# STM32H562 register map
File version: 0.1
CPU: CM33 r0p0, little endian, MPU, FPU, 4 interrupt priority bits
Registers are 32-bit, read-write, reset 0x0 unless marked. A register's access mark holds for its fields unless they carry their own. Offsets are from the block's base; [hi:lo] are bit positions; lines under a group give offsets from that group; {n}, {i} and the like mark numbered series.

## ADC1 — Analog to digital converter
Base 0x42028000
Same registers: ADC2 0x42028100, SEC_ADC1 0x52028000, SEC_ADC2 0x52028100
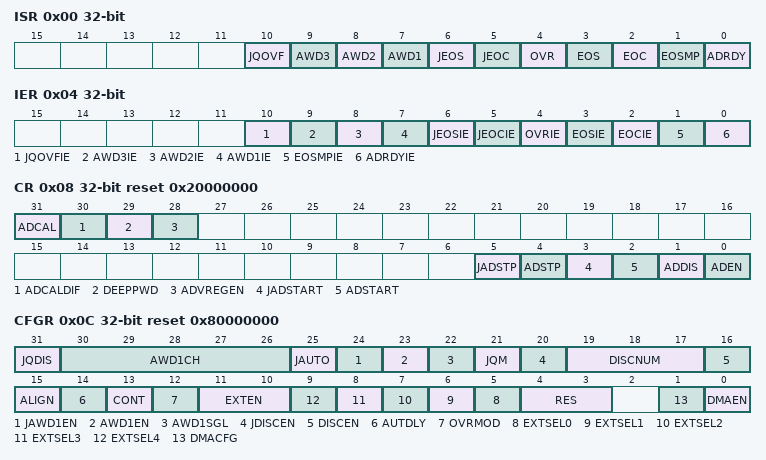
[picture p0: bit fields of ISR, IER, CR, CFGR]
0x00 ISR — ADC interrupt and status register
  [10] JQOVF — Injected context queue overflow This bit is set by hardware when an Overflow of the Injected Queue of Context occurs. It is cleared by software writing 1 to it. Refer to for more information.
  [9] AWD3 — Analog watchdog 3 flag This bit is set by hardware when the converted voltage crosses the values programmed in the fields LT3[7:0] and HT3[7:0] of ADC_TR3 register. It is cleared by software writing 1 to it.
  [8] AWD2 — Analog watchdog 2 flag This bit is set by hardware when the converted voltage crosses the values programmed in the fields LT2[7:0] and HT2[7:0] of ADC_TR2 register. It is cleared by software writing 1 to it.
  [7] AWD1 — Analog watchdog 1 flag This bit is set by hardware when the converted voltage crosses the values programmed in the fields LT1[11:0] and HT1[11:0] of ADC_TR1 register. It is cleared by software. writing 1 to it.
  [6] JEOS — Injected channel end of sequence flag This bit is set by hardware at the end of the conversions of all injected channels in the group. It is cleared by software writing 1 to it.
  [5] JEOC — Injected channel end of conversion flag This bit is set by hardware at the end of each injected conversion of a channel when a new data is available in the corresponding ADC_JDRy register. It is cleared by software writing 1 to it or by reading the corresponding ADC_JDRy register
  [4] OVR — ADC overrun This bit is set by hardware when an overrun occurs on a regular channel, meaning that a new conversion has completed while the EOC flag was already set. It is cleared by software writing 1 to it.
  [3] EOS — End of regular sequence flag This bit is set by hardware at the end of the conversions of a regular sequence of channels. It is cleared by software writing 1 to it.
  [2] EOC — End of conversion flag This bit is set by hardware at the end of each regular conversion of a channel when a new data is available in the ADC_DR register. It is cleared by software writing 1 to it or by reading the ADC_DR register
  [1] EOSMP — End of sampling flag This bit is set by hardware during the conversion of any channel (only for regular channels), at the end of the sampling phase.
  [0] ADRDY — ADC ready This bit is set by hardware after the ADC has been enabled (ADEN = 1) and when the ADC reaches a state where it is ready to accept conversion requests. It is cleared by software writing 1 to it.
0x04 IER — ADC interrupt enable register
  [10] JQOVFIE — Injected context queue overflow interrupt enable This bit is set and cleared by software to enable/disable the Injected Context Queue Overflow interrupt. Note: The software is allowed to write this bit only when JADSTART = 0 (which ensures that no injected conversion is ongoing).
  [9] AWD3IE — Analog watchdog 3 interrupt enable This bit is set and cleared by software to enable/disable the analog watchdog 2 interrupt. Note: The software is allowed to write this bit only when ADSTART = 0 and JADSTART = 0 (which ensures that no conversion is ongoing).
  [8] AWD2IE — Analog watchdog 2 interrupt enable This bit is set and cleared by software to enable/disable the analog watchdog 2 interrupt. Note: The software is allowed to write this bit only when ADSTART = 0 and JADSTART = 0 (which ensures that no conversion is ongoing).
  [7] AWD1IE — Analog watchdog 1 interrupt enable This bit is set and cleared by software to enable/disable the analog watchdog 1 interrupt. Note: The software is allowed to write this bit only when ADSTART = 0 and JADSTART = 0 (which ensures that no conversion is ongoing).
  [6] JEOSIE — End of injected sequence of conversions interrupt enable This bit is set and cleared by software to enable/disable the end of injected sequence of conversions interrupt. Note: The software is allowed to write this bit only when JADSTART = 0 (which ensures that no injected conversion is ongoing).
  [5] JEOCIE — End of injected conversion interrupt enable This bit is set and cleared by software to enable/disable the end of an injected conversion interrupt. Note: The software is allowed to write this bit only when JADSTART = 0 (which ensures that no injected conversion is ongoing).
  [4] OVRIE — Overrun interrupt enable This bit is set and cleared by software to enable/disable the Overrun interrupt of a regular conversion. Note: The software is allowed to write this bit only when ADSTART = 0 (which ensures that no regular conversion is ongoing).
  [3] EOSIE — End of regular sequence of conversions interrupt enable This bit is set and cleared by software to enable/disable the end of regular sequence of conversions interrupt. Note: The software is allowed to write this bit only when ADSTART = 0 (which ensures that no regular conversion is ongoing).
  [2] EOCIE — End of regular conversion interrupt enable This bit is set and cleared by software to enable/disable the end of a regular conversion interrupt. Note: The software is allowed to write this bit only when ADSTART = 0 (which ensures that no regular conversion is ongoing).
  [1] EOSMPIE — End of sampling flag interrupt enable for regular conversions This bit is set and cleared by software to enable/disable the end of the sampling phase interrupt for regular conversions. Note: The software is allowed to write this bit only when ADSTART = 0 (which ensures that no regular conversion is ongoing).
  [0] ADRDYIE — ADC ready interrupt enable This bit is set and cleared by software to enable/disable the ADC Ready interrupt. Note: The software is allowed to write this bit only when ADSTART = 0 and JADSTART = 0 (which ensures that no conversion is ongoing).
0x08 CR reset 0x20000000 — ADC control register
  [31] ADCAL — ADC calibration This bit is set by software to start the calibration of the ADC. Program first the bit ADCALDIF to determine if this calibration applies for Single-ended or Differential inputs mode. It is cleared by hardware after calibration is complete. Note: The software is allowed to launch a calibration by setting ADCAL only when ADEN = 0. The software is allowed to update the calibration factor by writing ADC_CALFACT only when ADEN = 1 and ADSTART = 0 and JADSTART = 0 (ADC enabled and no conversion is ongoing)
  [30] ADCALDIF — Differential mode for calibration This bit is set and cleared by software to configure the Single-ended or Differential inputs mode for the calibration. Note: The software is allowed to write this bit only when the ADC is disabled and is not calibrating (ADCAL = 0, JADSTART = 0, JADSTP = 0, ADSTART = 0, ADSTP = 0, ADDIS = 0 and ADEN = 0).
  [29] DEEPPWD — Deep-power-down enable This bit is set and cleared by software to put the ADC in Deep-power-down mode. Note: The software is allowed to write this bit only when the ADC is disabled (ADCAL = 0, JADSTART = 0, JADSTP = 0, ADSTART = 0, ADSTP = 0, ADDIS = 0 and ADEN = 0).
  [28] ADVREGEN — ADC voltage regulator enable This bits is set by software to enable the ADC voltage regulator. Before performing any operation such as launching a calibration or enabling the ADC, the ADC voltage regulator must first be enabled and the software must wait for the regulator start-up time. For more details about the ADC voltage regulator enable and disable sequences, refer to (ADVREGEN). The software can program this bit field only when the ADC is disabled (ADCAL = 0, JADSTART = 0, ADSTART = 0, ADSTP = 0, ADDIS = 0 and ADEN = 0).
  [5] JADSTP — ADC stop of injected conversion command This bit is set by software to stop and discard an ongoing injected conversion (JADSTP Command). It is cleared by hardware when the conversion is effectively discarded and the ADC injected sequence and triggers can be re-configured. The ADC is then ready to accept a new start of injected conversions (JADSTART command). Note: The software is allowed to set JADSTP only when JADSTART = 1 and ADDIS = 0 (ADC is enabled and eventually converting an injected conversion and there is no pending request to disable the ADC) In Auto-injection mode (JAUTO = 1), setting ADSTP bit aborts both regular and injected conversions (do not use JADSTP)
  [4] ADSTP — ADC stop of regular conversion command This bit is set by software to stop and discard an ongoing regular conversion (ADSTP Command). It is cleared by hardware when the conversion is effectively discarded and the ADC regular sequence and triggers can be re-configured. The ADC is then ready to accept a new start of regular conversions (ADSTART command). Note: The software is allowed to set ADSTP only when ADSTART = 1 and ADDIS = 0 (ADC is enabled and eventually converting a regular conversion and there is no pending request to disable the ADC). In auto-injection mode (JAUTO = 1), setting ADSTP bit aborts both regular and injected conversions (do not use JADSTP).
  [3] JADSTART — ADC start of injected conversion This bit is set by software to start ADC conversion of injected channels. Depending on the configuration bits JEXTEN, a conversion immediately starts (software trigger configuration) or once an injected hardware trigger event occurs (hardware trigger configuration). It is cleared by hardware: in Single conversion mode when software trigger is selected (JEXTSEL = 0x0): at the assertion of the End of Injected Conversion Sequence (JEOS) flag. in all cases: after the execution of the JADSTP command, at the same time that JADSTP is cleared by hardware. Note: The software is allowed to set JADSTART only when ADEN = 1 and ADDIS = 0 (ADC is enabled and there is no pending request to disable the ADC). In auto-injection mode (JAUTO = 1), regular and auto-injected conversions are started by setting bit ADSTART (JADSTART must be kept cleared)
  [2] ADSTART — ADC start of regular conversion This bit is set by software to start ADC conversion of regular channels. Depending on the configuration bits EXTEN, a conversion immediately starts (software trigger configuration) or once a regular hardware trigger event occurs (hardware trigger configuration). It is cleared by hardware: in Single conversion mode when software trigger is selected (EXTSEL = 0x0): at the assertion of the End of Regular Conversion Sequence (EOS) flag. in all cases: after the execution of the ADSTP command, at the same time that ADSTP is cleared by hardware. Note: The software is allowed to set ADSTART only when ADEN = 1 and ADDIS = 0 (ADC is enabled and there is no pending request to disable the ADC) In auto-injection mode (JAUTO = 1), regular and auto-injected conversions are started by setting bit ADSTART (JADSTART must be kept cleared)
  [1] ADDIS — ADC disable command This bit is set by software to disable the ADC (ADDIS command) and put it into power-down state (OFF state). It is cleared by hardware once the ADC is effectively disabled (ADEN is also cleared by hardware at this time). Note: The software is allowed to set ADDIS only when ADEN = 1 and both ADSTART = 0 and JADSTART = 0 (which ensures that no conversion is ongoing)
  [0] ADEN — ADC enable control This bit is set by software to enable the ADC. The ADC is effectively ready to operate once the flag ADRDY has been set. It is cleared by hardware when the ADC is disabled, after the execution of the ADDIS command. Note: The software is allowed to set ADEN only when all bits of ADC_CR registers are 0 (ADCAL = 0, JADSTART = 0, ADSTART = 0, ADSTP = 0, ADDIS = 0 and ADEN = 0) except for bit ADVREGEN which must be 1 (and the software must have wait for the startup time of the voltage regulator)
0x0C CFGR reset 0x80000000 — ADC configuration register
  [31] JQDIS — Injected Queue disable These bits are set and cleared by software to disable the Injected Queue mechanism : Note: The software is allowed to write this bit only when ADSTART = 0 and JADSTART = 0 (which ensures that no regular nor injected conversion is ongoing). A set or reset of JQDIS bit causes the injected queue to be flushed and the JSQR register is cleared.
  [30:26] AWD1CH — Analog watchdog 1 channel selection These bits are set and cleared by software. They select the input channel to be guarded by the analog watchdog. ..... others: reserved, must not be used Note: Some channels are not connected physically. Keep the corresponding AWD1CH[4:0] setting to the reset value. The channel selected by AWD1CH must be also selected into the SQRi or JSQRi registers. The software is allowed to write these bits only when ADSTART = 0 and JADSTART = 0 (which ensures that no conversion is ongoing).
  [25] JAUTO — Automatic injected group conversion This bit is set and cleared by software to enable/disable automatic injected group conversion after regular group conversion. Note: The software is allowed to write this bit only when ADSTART = 0 and JADSTART = 0 (which ensures that no regular nor injected conversion is ongoing). When dual mode is enabled (DUAL bits in ADC_CCR register are not equal to zero), the bit JAUTO of the slave ADC is no more writable and its content is equal to the bit JAUTO of the master ADC.
  [24] JAWD1EN — Analog watchdog 1 enable on injected channels This bit is set and cleared by software Note: The software is allowed to write this bit only when JADSTART = 0 (which ensures that no injected conversion is ongoing).
  [23] AWD1EN — Analog watchdog 1 enable on regular channels This bit is set and cleared by software Note: The software is allowed to write this bit only when ADSTART = 0 (which ensures that no regular conversion is ongoing).
  [22] AWD1SGL — Enable the watchdog 1 on a single channel or on all channels This bit is set and cleared by software to enable the analog watchdog on the channel identified by the AWD1CH[4:0] bits or on all the channels Note: The software is allowed to write these bits only when ADSTART = 0 and JADSTART = 0 (which ensures that no conversion is ongoing).
  [21] JQM — JSQR queue mode This bit is set and cleared by software. It defines how an empty Queue is managed. Refer to for more information. Note: The software is allowed to write this bit only when JADSTART = 0 (which ensures that no injected conversion is ongoing). When dual mode is enabled (DUAL bits in ADC_CCR register are not equal to zero), the bit JQM of the slave ADC is no more writable and its content is equal to the bit JQM of the master ADC.
  [20] JDISCEN — Discontinuous mode on injected channels This bit is set and cleared by software to enable/disable Discontinuous mode on the injected channels of a group. Note: The software is allowed to write this bit only when JADSTART = 0 (which ensures that no injected conversion is ongoing). It is not possible to use both auto-injected mode and Discontinuous mode simultaneously: the bits DISCEN and JDISCEN must be kept cleared by software when JAUTO is set. When dual mode is enabled (bits DUAL of ADC_CCR register are not equal to zero), the bit JDISCEN of the slave ADC is no more writable and its content is equal to the bit JDISCEN of the master ADC.
  [19:17] DISCNUM — Discontinuous mode channel count These bits are written by software to define the number of regular channels to be converted in Discontinuous mode, after receiving an external trigger. ... Note: The software is allowed to write these bits only when ADSTART = 0 (which ensures that no regular conversion is ongoing). When dual mode is enabled (DUAL bits in ADC_CCR register are not equal to zero), the bits DISCNUM[2:0] of the slave ADC are no more writable and their content is equal to the bits DISCNUM[2:0] of the master ADC.
  [16] DISCEN — Discontinuous mode for regular channels This bit is set and cleared by software to enable/disable Discontinuous mode for regular channels. Note: It is not possible to have both Discontinuous mode and Continuous mode enabled: it is forbidden to set both DISCEN = 1 and CONT = 1. It is not possible to use both auto-injected mode and Discontinuous mode simultaneously: the bits DISCEN and JDISCEN must be kept cleared by software when JAUTO is set. The software is allowed to write this bit only when ADSTART = 0 (which ensures that no regular conversion is ongoing). When dual mode is enabled (DUAL bits in ADC_CCR register are not equal to zero), the bit DISCEN of the slave ADC is no more writable and its content is equal to the bit DISCEN of the master ADC.
  [15] ALIGN — Data alignment This bit is set and cleared by software to select right or left alignment. Refer to register, data alignment and offset (ADC_DR, OFFSET, OFFSET_CH, ALIGN). Note: The software is allowed to write this bit only when ADSTART = 0 and JADSTART = 0 (which ensures that no conversion is ongoing).
  [14] AUTDLY — Delayed conversion mode This bit is set and cleared by software to enable/disable the Auto Delayed Conversion mode.. Note: The software is allowed to write this bit only when ADSTART = 0 and JADSTART = 0 (which ensures that no conversion is ongoing). When dual mode is enabled (DUAL bits in ADC_CCR register are not equal to zero), the bit AUTDLY of the slave ADC is no more writable and its content is equal to the bit AUTDLY of the master ADC.
  [13] CONT — Single / Continuous conversion mode for regular conversions This bit is set and cleared by software. If it is set, regular conversion takes place continuously until it is cleared. Note: It is not possible to have both Discontinuous mode and Continuous mode enabled: it is forbidden to set both DISCEN = 1 and CONT = 1. The software is allowed to write this bit only when ADSTART = 0 (which ensures that no regular conversion is ongoing). When dual mode is enabled (DUAL bits in ADC_CCR register are not equal to zero), the bit CONT of the slave ADC is no more writable and its content is equal to the bit CONT of the master ADC.
  [12] OVRMOD — Overrun mode This bit is set and cleared by software and configure the way data overrun is managed. Note: The software is allowed to write this bit only when ADSTART = 0 (which ensures that no regular conversion is ongoing).
  [11:10] EXTEN — External trigger enable and polarity selection for regular channels These bits are set and cleared by software to select the external trigger polarity and enable the trigger of a regular group. Note: The software is allowed to write these bits only when ADSTART = 0 (which ensures that no regular conversion is ongoing).
  [n+5] EXTSEL{n} (n=0..4) — External trigger selection for regular group These bits select the external event used to trigger the start of conversion of a regular group: ... Note: The software is allowed to write these bits only when ADSTART = 0 (which ensures that no regular conversion is ongoing).
  [4:3] RES — Data resolution These bits are written by software to select the resolution of the conversion. Note: The software is allowed to write these bits only when ADSTART = 0 and JADSTART = 0 (which ensures that no conversion is ongoing).
  [1] DMACFG — Direct memory access configuration This bit is set and cleared by software to select between two DMA modes of operation and is effective only when DMAEN = 1. For more details, refer to Note: The software is allowed to write this bit only when ADSTART = 0 and JADSTART = 0 (which ensures that no conversion is ongoing). In dual-ADC modes, this bit is not relevant and replaced by control bit DMACFG of the ADC_CCR register.
  [0] DMAEN — Direct memory access enable This bit is set and cleared by software to enable the generation of DMA requests. This allows to use the DMA to manage automatically the converted data. For more details, refer to conversions using the DMA. Note: The software is allowed to write this bit only when ADSTART = 0 and JADSTART = 0 (which ensures that no conversion is ongoing). In dual-ADC modes, this bit is not relevant and replaced by control bits MDMA[1:0] of the ADC_CCR register.
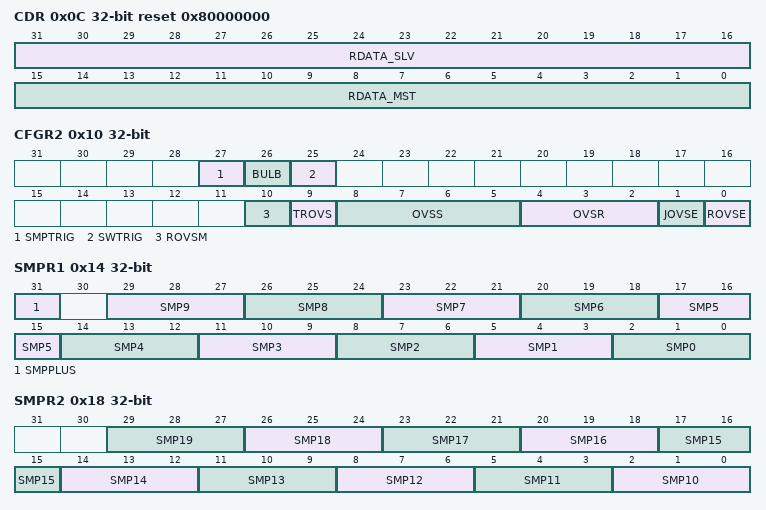
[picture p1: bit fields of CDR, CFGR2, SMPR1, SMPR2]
0x0C CDR ro reset 0x80000000 (alternate view of ADC_CFGR) — ADC_CDR_mode
  [31:16] RDATA_SLV — Regular data of the slave ADC In dual mode, these bits contain the regular data of the slave ADC. Refer to Dual ADC modes. The data alignment is applied as described in offset (ADC_DR, OFFSET, OFFSET_CH, ALIGN))
  [15:0] RDATA_MST — Regular data of the master ADC. In dual mode, these bits contain the regular data of the master ADC. Refer to . The data alignment is applied as described in offset (ADC_DR, OFFSET, OFFSET_CH, ALIGN)) In MDMA = 0b11 mode, bits 15:8 contains SLV_ADC_DR[7:0], bits 7:0 contains MST_ADC_DR[7:0].
0x10 CFGR2 — ADC configuration register 2
  [27] SMPTRIG — Sampling time control trigger mode This bit is set and cleared by software to enable the sampling time control trigger mode. The sampling time starts on the trigger rising edge, and the conversion on the trigger falling edge. EXTEN bit should be set to 01. BULB bit must not be set when the SMPTRIG bit is set. When EXTEN bit is set to 00, set SWTRIG to start the sampling and clear SWTRIG bit to start the conversion. Note: The software is allowed to write this bit only when ADSTART = 0 (which ensures that no conversion is ongoing).
  [26] BULB — Bulb sampling mode This bit is set and cleared by software to enable the bulb sampling mode. SAMPTRIG bit must not be set when the BULB bit is set. The very first ADC conversion is performed with the sampling time specified in SMPx bits. Note: The software is allowed to write this bit only when ADSTART = 0 (which ensures that no conversion is ongoing).
  [25] SWTRIG — Software trigger bit for sampling time control trigger mode This bit is set and cleared by software to enable the bulb sampling mode. Note: The software is allowed to write this bit only when ADSTART = 0 (which ensures that no conversion is ongoing).
  [10] ROVSM — Regular Oversampling mode This bit is set and cleared by software to select the regular oversampling mode. Note: The software is allowed to write this bit only when ADSTART = 0 (which ensures that no conversion is ongoing).
  [9] TROVS — Triggered Regular Oversampling This bit is set and cleared by software to enable triggered oversampling Note: The software is allowed to write this bit only when ADSTART = 0 (which ensures that no conversion is ongoing).
  [8:5] OVSS — Oversampling shift This bitfield is set and cleared by software to define the right shifting applied to the raw oversampling result. Other codes reserved Note: The software is allowed to write these bits only when ADSTART = 0 (which ensures that no conversion is ongoing).
  [4:2] OVSR — Oversampling ratio This bitfield is set and cleared by software to define the oversampling ratio. Note: The software is allowed to write these bits only when ADSTART = 0 (which ensures that no conversion is ongoing).
  [1] JOVSE — Injected Oversampling Enable This bit is set and cleared by software to enable injected oversampling. Note: The software is allowed to write this bit only when ADSTART = 0 and JADSTART = 0 (which ensures that no conversion is ongoing)
  [0] ROVSE — Regular Oversampling Enable This bit is set and cleared by software to enable regular oversampling. Note: The software is allowed to write this bit only when ADSTART = 0 and JADSTART = 0 (which ensures that no conversion is ongoing)
0x14 SMPR1 — ADC sample time register 1
  [31] SMPPLUS — Addition of one clock cycle to the sampling time. To make sure no conversion is ongoing, the software is allowed to write this bit only when ADSTART = 0 and JADSTART = 0.
  [3n+2:3n] SMP{n} (n=0..9) — Channel x sampling time selection These bits are written by software to select the sampling time individually for each channel. During sample cycles, the channel selection bits must remain unchanged. Note: The software is allowed to write these bits only when ADSTART = 0 and JADSTART = 0 (which ensures that no conversion is ongoing). Some channels are not connected physically. Keep the corresponding SMPx[2:0] setting to the reset value.
0x18 SMPR2 — ADC sample time register 2
  [3n-28:3n-30] SMP{n} (n=10..19) — Channel x sampling time selection These bits are written by software to select the sampling time individually for each channel. During sampling cycles, the channel selection bits must remain unchanged. Note: The software is allowed to write these bits only when ADSTART = 0 and JADSTART = 0 (which ensures that no conversion is ongoing). Some channels are not connected physically. Keep the corresponding SMPx[2:0] setting to the reset value.
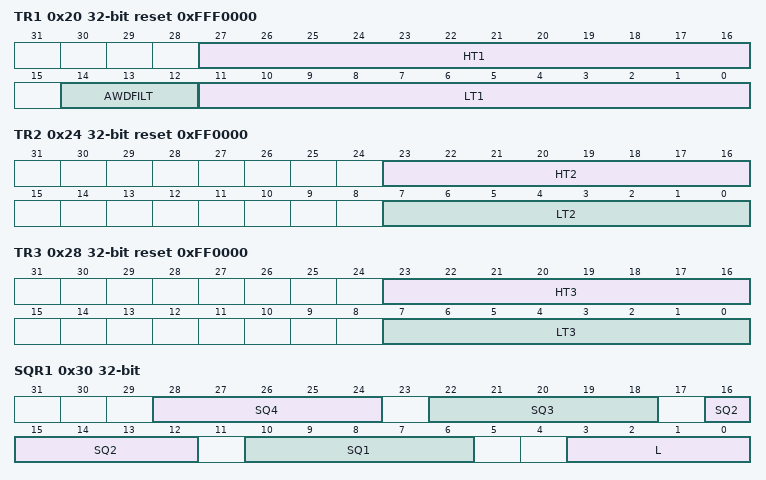
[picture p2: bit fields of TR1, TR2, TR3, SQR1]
0x20 TR1 reset 0xFFF0000 — ADC watchdog threshold register 1
  [27:16] HT1 — Analog watchdog 1 higher threshold These bits are written by software to define the higher threshold for the analog watchdog 1. Refer to AWD2CH, AWD3CH, AWD_HTx, AWD_LTx, AWDx) Note: The software is allowed to write these bits only when ADSTART = 0 and JADSTART = 0 (which ensures that no conversion is ongoing).
  [14:12] AWDFILT — Analog watchdog filtering parameter This bit is set and cleared by software. ... Note: The software is allowed to write this bit only when ADSTART = 0 (which ensures that no conversion is ongoing).
  [11:0] LT1 — Analog watchdog 1 lower threshold These bits are written by software to define the lower threshold for the analog watchdog 1. Refer to AWD2CH, AWD3CH, AWD_HTx, AWD_LTx, AWDx) Note: The software is allowed to write these bits only when ADSTART = 0 and JADSTART = 0 (which ensures that no conversion is ongoing).
0x24 TR2 reset 0xFF0000 — ADC watchdog threshold register 2
  [23:16] HT2 — Analog watchdog 2 higher threshold These bits are written by software to define the higher threshold for the analog watchdog 2. Refer to AWD2CH, AWD3CH, AWD_HTx, AWD_LTx, AWDx) Note: The software is allowed to write these bits only when ADSTART = 0 and JADSTART = 0 (which ensures that no conversion is ongoing).
  [7:0] LT2 — Analog watchdog 2 lower threshold These bits are written by software to define the lower threshold for the analog watchdog 2. Refer to AWD2CH, AWD3CH, AWD_HTx, AWD_LTx, AWDx) Note: The software is allowed to write these bits only when ADSTART = 0 and JADSTART = 0 (which ensures that no conversion is ongoing).
0x28 TR3 reset 0xFF0000 — ADC watchdog threshold register 3
  [23:16] HT3 — Analog watchdog 3 higher threshold These bits are written by software to define the higher threshold for the analog watchdog 3. Refer to AWD2CH, AWD3CH, AWD_HTx, AWD_LTx, AWDx) Note: The software is allowed to write these bits only when ADSTART = 0 and JADSTART = 0 (which ensures that no conversion is ongoing).
  [7:0] LT3 — Analog watchdog 3 lower threshold These bits are written by software to define the lower threshold for the analog watchdog 3. This watchdog compares the 8-bit of LT3 with the 8 MSB of the converted data. Note: The software is allowed to write these bits only when ADSTART = 0 and JADSTART = 0 (which ensures that no conversion is ongoing).
0x30 SQR1 — ADC regular sequence register 1
  [28:24] SQ4 — 4th conversion in regular sequence These bits are written by software with the channel number (0 to 19) assigned as the 4th in the regular conversion sequence. Note: The software is allowed to write these bits only when ADSTART = 0 (which ensures that no regular conversion is ongoing).
  [22:18] SQ3 — 3rd conversion in regular sequence These bits are written by software with the channel number (0 to 19) assigned as the 3rd in the regular conversion sequence. Note: The software is allowed to write these bits only when ADSTART = 0 (which ensures that no regular conversion is ongoing).
  [16:12] SQ2 — 2nd conversion in regular sequence These bits are written by software with the channel number (0 to 19) assigned as the 2nd in the regular conversion sequence. Note: The software is allowed to write these bits only when ADSTART = 0 (which ensures that no regular conversion is ongoing).
  [10:6] SQ1 — 1st conversion in regular sequence These bits are written by software with the channel number (0 to 19) assigned as the 1st in the regular conversion sequence. Note: The software is allowed to write these bits only when ADSTART = 0 (which ensures that no regular conversion is ongoing).
  [3:0] L — Regular channel sequence length These bits are written by software to define the total number of conversions in the regular channel conversion sequence. ... Note: The software is allowed to write these bits only when ADSTART = 0 (which ensures that no regular conversion is ongoing).
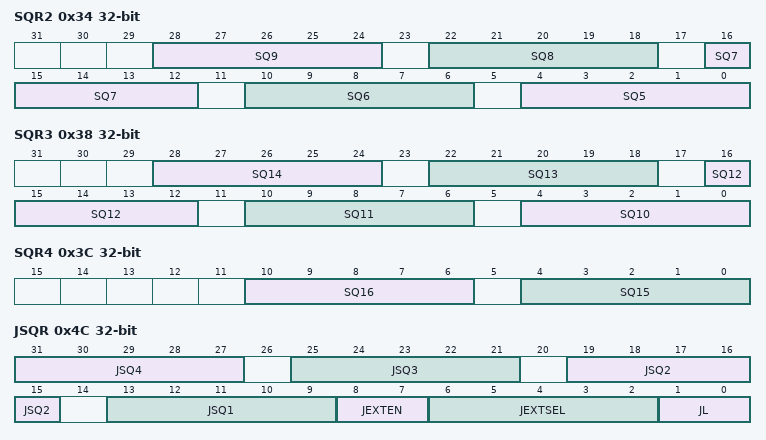
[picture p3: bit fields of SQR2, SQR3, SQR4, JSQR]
0x34 SQR2 — ADC regular sequence register 2
  [28:24] SQ9 — 9th conversion in regular sequence These bits are written by software with the channel number (0 to 19) assigned as the 9th in the regular conversion sequence. Note: The software is allowed to write these bits only when ADSTART = 0 (which ensures that no regular conversion is ongoing).
  [22:18] SQ8 — 8th conversion in regular sequence These bits are written by software with the channel number (0 to 19) assigned as the 8th in the regular conversion sequence Note: The software is allowed to write these bits only when ADSTART = 0 (which ensures that no regular conversion is ongoing).
  [16:12] SQ7 — 7th conversion in regular sequence These bits are written by software with the channel number (0 to 19) assigned as the 7th in the regular conversion sequence. Note: The software is allowed to write these bits only when ADSTART = 0 (which ensures that no regular conversion is ongoing).
  [10:6] SQ6 — 6th conversion in regular sequence These bits are written by software with the channel number (0 to 19) assigned as the 6th in the regular conversion sequence. Note: The software is allowed to write these bits only when ADSTART = 0 (which ensures that no regular conversion is ongoing).
  [4:0] SQ5 — 5th conversion in regular sequence These bits are written by software with the channel number (0 to 19) assigned as the 5th in the regular conversion sequence. Note: The software is allowed to write these bits only when ADSTART = 0 (which ensures that no regular conversion is ongoing).
0x38 SQR3 — ADC regular sequence register 3
  [6n-56:6n-60] SQ{n} (n=10..14) — {n}th conversion in regular sequence These bits are written by software with the channel number (0 to 19) assigned as the {n}th in the regular conversion sequence. Note: The software is allowed to write these bits only when ADSTART = 0 (which ensures that no regular conversion is ongoing).
0x3C SQR4 — ADC regular sequence register 4
  [10:6] SQ16 — 16th conversion in regular sequence These bits are written by software with the channel number (0 to 19) assigned as the 16th in the regular conversion sequence. Note: The software is allowed to write these bits only when ADSTART = 0 (which ensures that no regular conversion is ongoing).
  [4:0] SQ15 — 15th conversion in regular sequence These bits are written by software with the channel number (0 to 19) assigned as the 15th in the regular conversion sequence. Note: The software is allowed to write these bits only when ADSTART = 0 (which ensures that no regular conversion is ongoing).
0x40 DR ro — ADC regular data register
  [15:0] RDATA — Regular data converted These bits are read-only. They contain the conversion result from the last converted regular channel. The data are left- or right-aligned as described in .
0x4C JSQR — ADC injected sequence register
  [31:27] JSQ4 — 4th conversion in the injected sequence These bits are written by software with the channel number (0 to 19) assigned as the 4th in the injected conversion sequence. Note: The software is allowed to write these bits only when JADSTART = 0 (which ensures that no injected conversion is ongoing).
  [25:21] JSQ3 — 3rd conversion in the injected sequence These bits are written by software with the channel number (0 to 19) assigned as the 3rd in the injected conversion sequence. Note: The software is allowed to write these bits only when JADSTART = 0 (which ensures that no injected conversion is ongoing).
  [19:15] JSQ2 — 2nd conversion in the injected sequence These bits are written by software with the channel number (0 to 19) assigned as the 2nd in the injected conversion sequence. Note: The software is allowed to write these bits only when JADSTART = 0 (which ensures that no injected conversion is ongoing).
  [13:9] JSQ1 — 1st conversion in the injected sequence These bits are written by software with the channel number (0 to 19) assigned as the 1st in the injected conversion sequence. Note: The software is allowed to write these bits only when JADSTART = 0 (which ensures that no injected conversion is ongoing).
  [8:7] JEXTEN — External trigger enable and polarity selection for injected channels These bits are set and cleared by software to select the external trigger polarity and enable the trigger of an injected group. Note: The software is allowed to write these bits only when JADSTART = 0 (which ensures that no injected conversion is ongoing). If JQM = 1 and if the Queue of Context becomes empty, the software and hardware triggers of the injected sequence are both internally disabled (refer to Queue of context for injected conversions)
  [6:2] JEXTSEL — External Trigger Selection for injected group These bits select the external event used to trigger the start of conversion of an injected group: ... Note: The software is allowed to write these bits only when JADSTART = 0 (which ensures that no injected conversion is ongoing).
  [1:0] JL — Injected channel sequence length These bits are written by software to define the total number of conversions in the injected channel conversion sequence. Note: The software is allowed to write these bits only when JADSTART = 0 (which ensures that no injected conversion is ongoing).
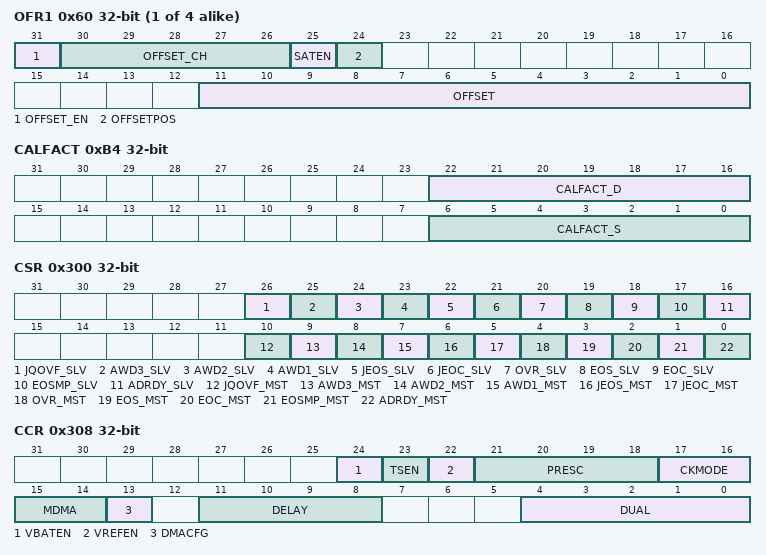
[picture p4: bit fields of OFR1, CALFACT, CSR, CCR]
{0x5C+4i} OFR{i} (i=1..4) — ADC offset {i} register
  [31] OFFSET_EN — Offset y enable This bit is written by software to enable or disable the offset programmed into bits OFFSET[11:0]. Note: The software is allowed to write this bit only when ADSTART = 0 and JADSTART = 0 (which ensures that no conversion is ongoing).
  [30:26] OFFSET_CH — Channel selection for the data offset y These bits are written by software to define the channel to which the offset programmed into bits OFFSET[11:0] applies. Note: The software is allowed to write these bits only when ADSTART = 0 and JADSTART = 0 (which ensures that no conversion is ongoing). Some channels are not connected physically and must not be selected for the data offset y. If OFFSET_EN is set, it is not allowed to select the same channel for different ADC_OFRy registers.
  [25] SATEN — Saturation enable This bit is set and cleared by software to enable the saturation at 0x000 and 0xFFF for the offset function. Note: The software is allowed to write these bits only when ADSTART = 0 and JADSTART = 0 (which ensures that no conversion is ongoing).
  [24] OFFSETPOS — Positive offset This bit is set and cleared by software to enable the positive offset. Note: The software is allowed to write these bits only when ADSTART = 0 and JADSTART = 0 (which ensures that no conversion is ongoing).
  [11:0] OFFSET — Data offset y for the channel programmed into bits OFFSET_CH[4:0] These bits are written by software to define the offset to be subtracted from the raw converted data when converting a channel (can be regular or injected). The channel to which applies the data offset must be programmed in the bits OFFSET_CH[4:0]. The conversion result can be read from in the ADC_DR (regular conversion) or from in the ADC_JDRyi registers (injected conversion). Note: The software is allowed to write these bits only when ADSTART = 0 and JADSTART = 0 (which ensures that no conversion is ongoing). If several offset (OFFSET) point to the same channel, only the offset with the lowest x value is considered for the subtraction. Ex: if OFFSET1_CH[4:0] = 4 and OFFSET2_CH[4:0] = 4, this is OFFSET1[11:0] which is subtracted when converting channel 4.
{0x7C+4i} JDR{i} ro (i=1..4) — ADC injected channel {i} data register
  [15:0] JDATA — Injected data These bits are read-only. They contain the conversion result from injected channel y. The data are left -or right-aligned as described in .
0xA0 AWD2CR — ADC Analog Watchdog 2 Configuration Register
  [19:0] AWD2CH — Analog watchdog 2 channel selection These bits are set and cleared by software. They enable and select the input channels to be guarded by the analog watchdog 2. AWD2CH[i] = 0: ADC analog input channel i is not monitored by AWD2 AWD2CH[i] = 1: ADC analog input channel i is monitored by AWD2 When AWD2CH[19:0] = 000..0, the analog Watchdog 2 is disabled Note: The channels selected by AWD2CH must be also selected into the SQRi or JSQRi registers. The software is allowed to write these bits only when ADSTART = 0 and JADSTART = 0 (which ensures that no conversion is ongoing). Some channels are not connected physically and must not be selected for the analog watchdog.
0xA4 AWD3CR — ADC Analog Watchdog 3 Configuration Register
  [19:0] AWD3CH — Analog watchdog 3 channel selection These bits are set and cleared by software. They enable and select the input channels to be guarded by the analog watchdog 3. AWD3CH[i] = 0: ADC analog input channel i is not monitored by AWD3 AWD3CH[i] = 1: ADC analog input channel i is monitored by AWD3 When AWD3CH[19:0] = 000..0, the analog Watchdog 3 is disabled Note: The channels selected by AWD3CH must be also selected into the SQRi or JSQRi registers. The software is allowed to write these bits only when ADSTART = 0 and JADSTART = 0 (which ensures that no conversion is ongoing). Some channels are not connected physically and must not be selected for the analog watchdog.
0xB0 DIFSEL — ADC Differential mode Selection Register
  [19:0] DIFSEL — Differential mode for channels 19 to 0. These bits are set and cleared by software. They allow to select if a channel is configured as Single-ended or Differential mode. DIFSEL[i] = 0: ADC analog input channel is configured in Single-ended mode DIFSEL[i] = 1: ADC analog input channel i is configured in Differential mode Note: The DIFSEL bits corresponding to channels that are either connected to a single-ended I/O port or to an internal channel must be kept their reset value (Single-ended input mode). The software is allowed to write these bits only when the ADC is disabled (ADCAL = 0, JADSTART = 0, JADSTP = 0, ADSTART = 0, ADSTP = 0, ADDIS = 0 and ADEN = 0).
0xB4 CALFACT — ADC Calibration Factors
  [22:16] CALFACT_D — Calibration Factors in differential mode These bits are written by hardware or by software. Once a differential inputs calibration is complete, they are updated by hardware with the calibration factors. Software can write these bits with a new calibration factor. If the new calibration factor is different from the current one stored into the analog ADC, it is then applied once a new differential calibration is launched. Note: The software is allowed to write these bits only when ADEN = 1, ADSTART = 0 and JADSTART = 0 (ADC is enabled and no calibration is ongoing and no conversion is ongoing).
  [6:0] CALFACT_S — Calibration Factors In Single-ended mode These bits are written by hardware or by software. Once a single-ended inputs calibration is complete, they are updated by hardware with the calibration factors. Software can write these bits with a new calibration factor. If the new calibration factor is different from the current one stored into the analog ADC, it is then applied once a new single-ended calibration is launched. Note: The software is allowed to write these bits only when ADEN = 1, ADSTART = 0 and JADSTART = 0 (ADC is enabled and no calibration is ongoing and no conversion is ongoing).
0xC8 OR — ADC option register
  [0] OP0 — VDDCORE channel enable
0x300 CSR ro — ADC common status register
  [26] JQOVF_SLV — Injected Context Queue Overflow flag of the slave ADC This bit is a copy of the JQOVF bit in the corresponding ADC_ISR register.
  [25] AWD3_SLV — Analog watchdog 3 flag of the slave ADC This bit is a copy of the AWD3 bit in the corresponding ADC_ISR register.
  [24] AWD2_SLV — Analog watchdog 2 flag of the slave ADC This bit is a copy of the AWD2 bit in the corresponding ADC_ISR register.
  [23] AWD1_SLV — Analog watchdog 1 flag of the slave ADC This bit is a copy of the AWD1 bit in the corresponding ADC_ISR register.
  [22] JEOS_SLV — End of injected sequence flag of the slave ADC This bit is a copy of the JEOS bit in the corresponding ADC_ISR register.
  [21] JEOC_SLV — End of injected conversion flag of the slave ADC This bit is a copy of the JEOC bit in the corresponding ADC_ISR register.
  [20] OVR_SLV — Overrun flag of the slave ADC This bit is a copy of the OVR bit in the corresponding ADC_ISR register.
  [19] EOS_SLV — End of regular sequence flag of the slave ADC. This bit is a copy of the EOS bit in the corresponding ADC_ISR register.
  [18] EOC_SLV — End of regular conversion of the slave ADC This bit is a copy of the EOC bit in the corresponding ADC_ISR register.
  [17] EOSMP_SLV — End of Sampling phase flag of the slave ADC This bit is a copy of the EOSMP2 bit in the corresponding ADC_ISR register.
  [16] ADRDY_SLV — Slave ADC ready This bit is a copy of the ADRDY bit in the corresponding ADC_ISR register.
  [10] JQOVF_MST — Injected Context Queue Overflow flag of the master ADC This bit is a copy of the JQOVF bit in the corresponding ADC_ISR register.
  [9] AWD3_MST — Analog watchdog 3 flag of the master ADC This bit is a copy of the AWD3 bit in the corresponding ADC_ISR register.
  [8] AWD2_MST — Analog watchdog 2 flag of the master ADC This bit is a copy of the AWD2 bit in the corresponding ADC_ISR register.
  [7] AWD1_MST — Analog watchdog 1 flag of the master ADC This bit is a copy of the AWD1 bit in the corresponding ADC_ISR register.
  [6] JEOS_MST — End of injected sequence flag of the master ADC This bit is a copy of the JEOS bit in the corresponding ADC_ISR register.
  [5] JEOC_MST — End of injected conversion flag of the master ADC This bit is a copy of the JEOC bit in the corresponding ADC_ISR register.
  [4] OVR_MST — Overrun flag of the master ADC This bit is a copy of the OVR bit in the corresponding ADC_ISR register.
  [3] EOS_MST — End of regular sequence flag of the master ADC This bit is a copy of the EOS bit in the corresponding ADC_ISR register.
  [2] EOC_MST — End of regular conversion of the master ADC This bit is a copy of the EOC bit in the corresponding ADC_ISR register.
  [1] EOSMP_MST — End of Sampling phase flag of the master ADC This bit is a copy of the EOSMP bit in the corresponding ADC_ISR register.
  [0] ADRDY_MST — Master ADC ready This bit is a copy of the ADRDY bit in the corresponding ADC_ISR register.
0x308 CCR — ADC common control register
  [24] VBATEN — VBAT enable This bit is set and cleared by software to control.
  [23] TSEN — VSENSE enable This bit is set and cleared by software to control VSENSE.
  [22] VREFEN — VREFINT enable This bit is set and cleared by software to enable/disable the VREFINT channel.
  [21:18] PRESC — ADC prescaler These bits are set and cleared by software to select the frequency of the clock to the ADC. The clock is common for all the ADCs. other: reserved Note: The software is allowed to write these bits only when the ADC is disabled (ADCAL = 0, JADSTART = 0, ADSTART = 0, ADSTP = 0, ADDIS = 0 and ADEN = 0). The ADC prescaler value is applied only when CKMODE[1:0] = 0b00.
  [17:16] CKMODE — ADC clock mode These bits are set and cleared by software to define the ADC clock scheme (which is common to both master and slave ADCs): In all synchronous clock modes, there is no jitter in the delay from a timer trigger to the start of a conversion. Note: The software is allowed to write these bits only when the ADCs are disabled (ADCAL = 0, JADSTART = 0, ADSTART = 0, ADSTP = 0, ADDIS = 0 and ADEN = 0).
  [15:14] MDMA — Direct memory access mode for dual ADC mode This bitfield is set and cleared by software. Refer to the DMA controller section for more details. Note: The software is allowed to write these bits only when ADSTART = 0 (which ensures that no regular conversion is ongoing).
  [13] DMACFG — DMA configuration (for dual ADC mode) This bit is set and cleared by software to select between two DMA modes of operation and is effective only when DMAEN = 1. For more details, refer to Note: The software is allowed to write these bits only when ADSTART = 0 (which ensures that no regular conversion is ongoing).
  [11:8] DELAY — Delay between 2 sampling phases These bits are set and cleared by software. These bits are used in dual interleaved modes. Refer to for the value of ADC resolution versus DELAY bits values. Note: The software is allowed to write these bits only when the ADCs are disabled (ADCAL = 0, JADSTART = 0, ADSTART = 0, ADSTP = 0, ADDIS = 0 and ADEN = 0).
  [4:0] DUAL — Dual ADC mode selection These bits are written by software to select the operating mode. 0 value means Independent Mode. Values 00001 to 01001 means Dual mode, master and slave ADCs are working together. All other combinations are reserved and must not be programmed Note: The software is allowed to write these bits only when the ADCs are disabled (ADCAL = 0, JADSTART = 0, ADSTART = 0, ADSTP = 0, ADDIS = 0 and ADEN = 0).
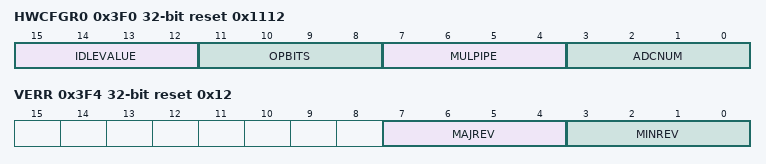
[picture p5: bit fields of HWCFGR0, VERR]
0x3F0 HWCFGR0 ro reset 0x1112 — ADC hardware configuration register
  [15:12] IDLEVALUE — Idle value for non-selected channels
  [11:8] OPBITS — Number of option bits
  [7:4] MULPIPE — Number of pipeline stages
  [3:0] ADCNUM — Number of ADCs implemented
0x3F4 VERR ro reset 0x12 — ADC version register
  [7:4] MAJREV — Major revision These bits returns the ADC IP major revision
  [3:0] MINREV — Minor revision These bits returns the ADC IP minor revision 0002: Major revision = X.2
0x3F8 IPDR ro reset 0x110006 — ADC identification register
  [31:0] ID — Peripheral identifier These bits returns the ADC identifier. ID[31:0] = 0x0011 0006: c7amba_aditf5_90_v1
0x3FC SIDR ro reset 0xA3C5DD01 — ADC size identification register
  [31:0] SID — Size Identification SID[31:8]: fixed code that characterizes the ADC_SIDR register. This field is always read at 0xA3C5DD. SID[7:0]: read-only numeric field that returns the address offset (in Kbytes) of the identification registers from the IP base address:
